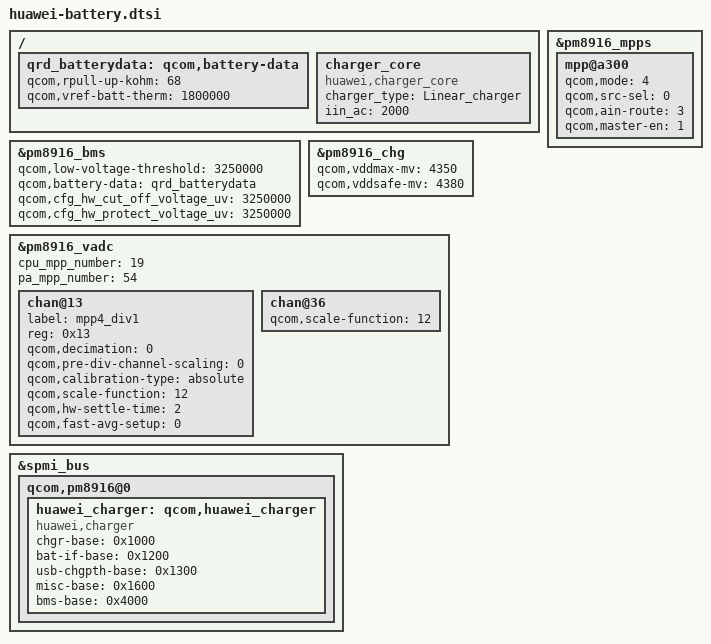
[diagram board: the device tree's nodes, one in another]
/* do not use default battery values */
/ {
        qrd_batterydata: qcom,battery-data {
                qcom,rpull-up-kohm = <68>;
                qcom,vref-batt-therm = <1800000>;
		#include "HB4242B4EBW_ATL_SCUD-4v35-3000mah.dtsi"
		#include "HB4242B4EBW_LG_SWD-4v35-3000mah.dtsi"
		#include "HB4342B4EBW_CLT_GY-4v35-3000mah.dtsi"
        };
};

&pm8916_bms {
        status = "ok";
        qcom,low-voltage-threshold = <3250000>;
        qcom,battery-data = <&qrd_batterydata>;
	qcom,cfg_hw_cut_off_voltage_uv = <3250000>;
	qcom,cfg_hw_protect_voltage_uv = <3250000>;
};

&pm8916_chg {
        status = "okay";
        qcom,vddmax-mv = <4350>;
        qcom,vddsafe-mv = <4380>;
};

&pm8916_mpps {
	mpp@a300 {
		qcom,mode = <4>; // QPNP_PIN_MODE_AIN
		qcom,src-sel = <0>; // QPNP_PIN_SEL_FUNC_CONSTANT
		qcom,ain-route = <3>; // QPNP_PIN_AIN_AMUX_CH8
		qcom,master-en = <1>; // Enable features
	};
};

&pm8916_vadc {
	cpu_mpp_number = <19>;
	pa_mpp_number = <54>;

	chan@13 {
		label = "mpp4_div1";
		reg = <0x13>;
		qcom,decimation = <0>; //512 sampling rate
		qcom,pre-div-channel-scaling = <0>; //1:1 scaling
		qcom,calibration-type = "absolute"; //Use 625mV & 1.25V reference voltage
		qcom,scale-function = <12>; //convert raw adc code to voltage
		qcom,hw-settle-time = <2>; //200us
		qcom,fast-avg-setup = <0>; //with only one average measurement
	};

	chan@36 {
		qcom,scale-function = <12>;
	};
};
/{
	charger_core: charger_core{
		compatible = "huawei,charger_core";
		charger_type = "Linear_charger";
		iin_ac = <2000>;
		status = "ok";
	};
};

&spmi_bus{
	qcom,pm8916@0 {
		huawei_charger: qcom,huawei_charger{
			compatible = "huawei,charger";
			chgr-base = <0x1000>;
			bat-if-base = <0x1200>;
			usb-chgpth-base = <0x1300>;
			misc-base = <0x1600>;
			bms-base = <0x4000>;
			status = "ok";
		};
	};
};
